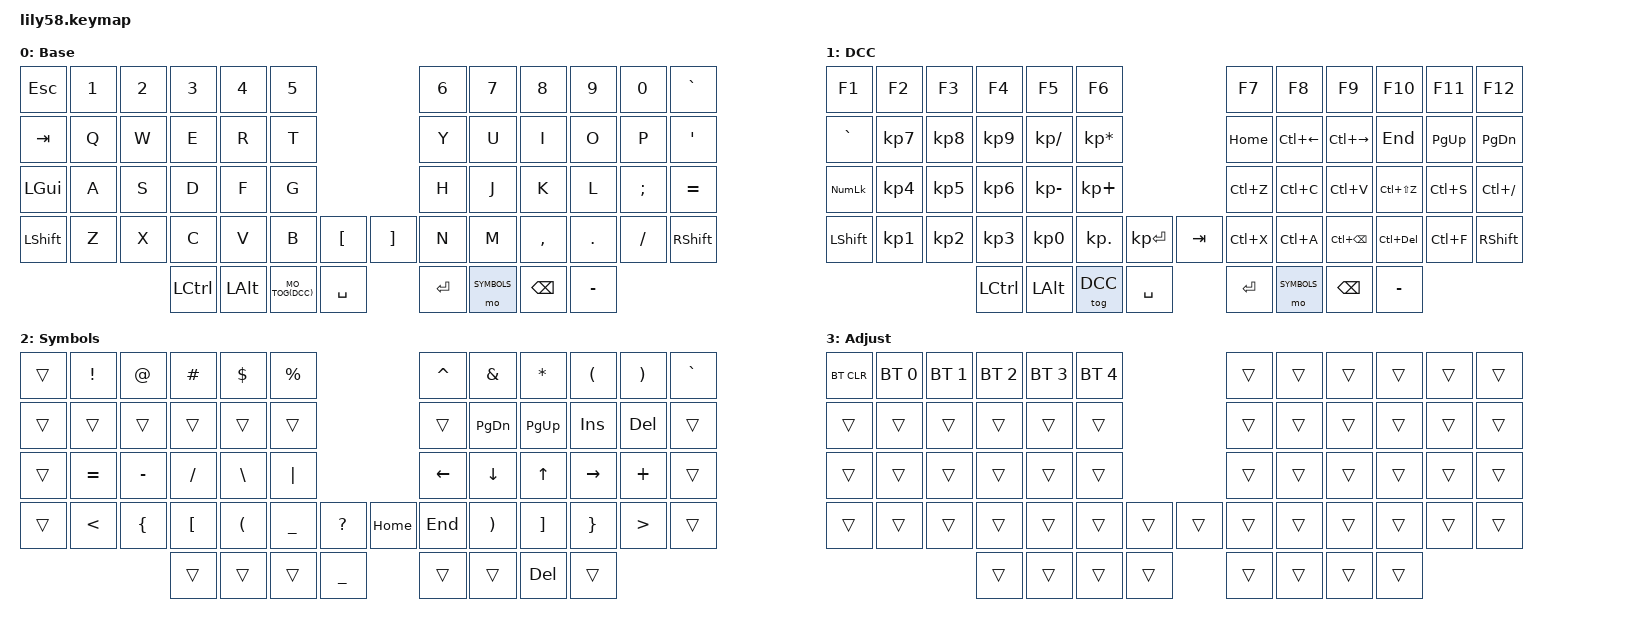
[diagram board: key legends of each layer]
/*
 * Copyright (c) 2020 The ZMK Contributors
 *
 * SPDX-License-Identifier: MIT
 */

#include <behaviors.dtsi>
#include <dt-bindings/zmk/keys.h>
#include <dt-bindings/zmk/bt.h>
#include <dt-bindings/zmk/ext_power.h>

#define BASE     0
#define DCC      1
#define SYMBOLS  2
#define ADJUST   3

#define MO_TOG(layer) &mo_tog layer layer

/ {
    behaviors {
        mo_tog: behavior_mo_tog {
            compatible = "zmk,behavior-hold-tap";
            #binding-cells = <2>;
            flavor = "hold-preferred";
            tapping-term-ms = <200>;
            bindings = <&mo>, <&tog>;
        };
    };

    /* DCC and SYMBOLS active together activate ADJUST, including toggled DCC. */
    conditional_layers {
        compatible = "zmk,conditional-layers";

        adjust_layer {
            if-layers = <DCC SYMBOLS>;
            then-layer = <ADJUST>;
        };
    };

    keymap {
        compatible = "zmk,keymap";

        default_layer {
            display-name = "Base";

            bindings = <
&kp ESC   &kp N1 &kp N2 &kp N3   &kp N4   &kp N5                     &kp N6 &kp N7   &kp N8    &kp N9  &kp N0   &kp GRAVE
&kp TAB   &kp Q  &kp W  &kp E    &kp R    &kp T                      &kp Y  &kp U    &kp I     &kp O   &kp P    &kp SQT
&kp LGUI  &kp A  &kp S  &kp D    &kp F    &kp G                      &kp H  &kp J    &kp K     &kp L   &kp SEMI &kp EQUAL
&kp LSHFT &kp Z  &kp X  &kp C    &kp V    &kp B  &kp LBKT   &kp RBKT &kp N  &kp M    &kp COMMA &kp DOT &kp FSLH &kp RSHFT
                        &kp LCTRL &kp LALT MO_TOG(DCC) &kp SPACE      &kp RET &mo SYMBOLS &kp BSPC &kp MINUS
            >;

            sensor-bindings = <&inc_dec_kp C_VOL_UP C_VOL_DN>;
        };

        /*
         * Tap DCC to toggle this layer. Hold DCC while pressing another key
         * to use it momentarily.
         * F1-F12 run left to right across the entire number row.
         * Num Lock is on the left outer home-row key (Super on Base).
         * Right home row: Undo, Copy, Paste, Redo, Save, Comment.
         * These are ordinary Ctrl chords: held Shift passes through, so
         * Shift + Copy/Paste sends Ctrl+Shift+C/V for terminal shortcuts.
         * Redo is Ctrl+Shift+Z; comment is Ctrl+/ (application dependent).
         */
        dcc_layer {
            display-name = "DCC";

            bindings = <
&kp F1     &kp F2    &kp F3    &kp F4    &kp F5        &kp F6                             &kp F7       &kp F8        &kp F9       &kp F10       &kp F11  &kp F12
&kp GRAVE  &kp KP_N7 &kp KP_N8 &kp KP_N9 &kp KP_DIVIDE &kp KP_MULTIPLY                    &kp HOME     &kp LC(LEFT)  &kp LC(RIGHT) &kp END       &kp PG_UP &kp PG_DN
&kp KP_NUM &kp KP_N4 &kp KP_N5 &kp KP_N6 &kp KP_MINUS  &kp KP_PLUS                        &kp LC(Z)    &kp LC(C)     &kp LC(V)    &kp LC(LS(Z)) &kp LC(S) &kp LC(FSLH)
&kp LSHFT  &kp KP_N1 &kp KP_N2 &kp KP_N3 &kp KP_N0     &kp KP_DOT &kp KP_ENTER   &kp TAB   &kp LC(X)    &kp LC(A)     &kp LC(BSPC) &kp LC(DEL)   &kp LC(F) &kp RSHFT
                                    &kp LCTRL &kp LALT &tog DCC &kp SPACE                   &kp RET      &mo SYMBOLS   &kp BSPC     &kp MINUS
            >;

            sensor-bindings = <&inc_dec_kp C_VOL_UP C_VOL_DN>;
        };

        /*
         * Programming symbols and navigation.
         * SYMBOLS + Space is underscore; SYMBOLS + Backspace is Delete.
         * H J K L = Left Down Up Right. End is on N, directly below H.
         * Lower-row pairs mirror across the split:
         * Z / = < >; X . = { }; C , = [ ]; V M = ( ).
         */
        symbols_layer {
            display-name = "Symbols";

            bindings = <
&trans &kp EXCL  &kp AT    &kp HASH  &kp DOLLAR &kp PRCNT                       &kp CARET &kp AMPS  &kp ASTRK &kp LPAR  &kp RPAR &kp GRAVE
&trans &trans    &trans    &trans    &trans     &trans                          &trans    &kp PG_DN &kp PG_UP &kp INS   &kp DEL  &trans
&trans &kp EQUAL &kp MINUS &kp FSLH  &kp BSLH   &kp PIPE                        &kp LEFT  &kp DOWN  &kp UP    &kp RIGHT &kp PLUS &trans
&trans &kp LT    &kp LBRC  &kp LBKT  &kp LPAR   &kp UNDER &kp QMARK  &kp HOME  &kp END   &kp RPAR  &kp RBKT  &kp RBRC  &kp GT   &trans
                              &trans  &trans     &trans    &kp UNDER    &trans    &trans    &kp DEL   &trans
            >;

            sensor-bindings = <&inc_dec_kp C_VOL_UP C_VOL_DN>;
        };

        /* Activate both thumb layers to reach Bluetooth controls. */
        adjust_layer {
            display-name = "Adjust";

            bindings = <
&bt BT_CLR &bt BT_SEL 0 &bt BT_SEL 1 &bt BT_SEL 2 &bt BT_SEL 3 &bt BT_SEL 4    &trans &trans &trans &trans &trans &trans
&trans     &trans       &trans       &trans       &trans       &trans          &trans &trans &trans &trans &trans &trans
&trans     &trans       &trans       &trans       &trans       &trans          &trans &trans &trans &trans &trans &trans
&trans     &trans       &trans       &trans       &trans       &trans &trans    &trans &trans &trans &trans &trans &trans &trans
                                          &trans &trans &trans &trans          &trans &trans &trans &trans
            >;

            sensor-bindings = <&inc_dec_kp C_VOL_UP C_VOL_DN>;
        };

        /* Preserve two dynamic slots for ZMK Studio. */
        extra_2 {
            status = "reserved";
        };

        extra_3 {
            status = "reserved";
        };
    };
};
